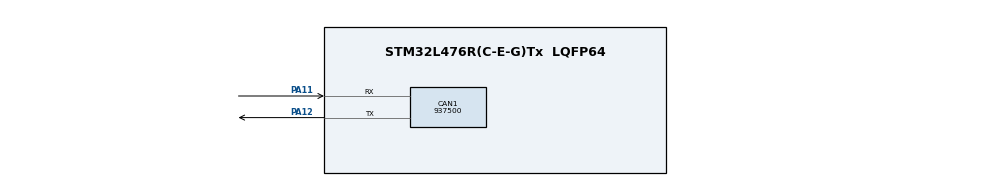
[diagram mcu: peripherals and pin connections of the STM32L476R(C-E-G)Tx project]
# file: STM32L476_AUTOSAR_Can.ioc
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CAN1.CalculateBaudRate=937500
CAN1.CalculateTimeBit=1066
CAN1.CalculateTimeQuantum=355.55555555555554
Mcu.Family=STM32L4
Mcu.Name=STM32L476R(C-E-G)Tx
Mcu.Package=LQFP64
NVIC.PriorityGroup=NVIC_PRIORITYGROUP_4
PA11.Mode=CAN_Activate
PA11.Signal=CAN1_RX
PA12.Mode=CAN_Activate
PA12.Signal=CAN1_TX
PC14-OSC32_IN\ (PC14).Mode=LSE-External-Oscillator
PC14-OSC32_IN\ (PC14).Signal=RCC_OSC32_IN
PC15-OSC32_OUT\ (PC15).Mode=LSE-External-Oscillator
PC15-OSC32_OUT\ (PC15).Signal=RCC_OSC32_OUT
PH0-OSC_IN\ (PH0).Mode=HSE-External-Oscillator
PH0-OSC_IN\ (PH0).Signal=RCC_OSC_IN
PH1-OSC_OUT\ (PH1).Mode=HSE-External-Oscillator
PH1-OSC_OUT\ (PH1).Signal=RCC_OSC_OUT
ProjectManager.HeapSize=0x200
ProjectManager.StackSize=0x400
ProjectManager.TargetToolchain=MDK-ARM V5.32
RCC.ADCFreq_Value=16000000
RCC.AHBFreq_Value=45000000
RCC.APB1Freq_Value=45000000
RCC.APB1TimFreq_Value=45000000
RCC.APB2Freq_Value=45000000
RCC.APB2TimFreq_Value=45000000
RCC.CortexFreq_Value=45000000
RCC.HCLKFreq_Value=45000000
RCC.HSE_VALUE=8000000
RCC.HSI_VALUE=16000000
RCC.MSI_VALUE=4000000
RCC.PLLM=4
RCC.PLLN=45
RCC.PLLR=RCC_PLLR_DIV4
RCC.PLLSourceVirtual=RCC_PLLSOURCE_HSI
RCC.PREFETCH_ENABLE=1
RCC.SYSCLKFreq_VALUE=45000000
RCC.SYSCLKSource=RCC_SYSCLKSOURCE_PLLCLK
RCC.USBFreq_Value=16000000
RCC.VCOOutputFreq_Value=180000000
board=NUCLEO-L476RG

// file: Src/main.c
/* USER CODE BEGIN Header */
/**
  ******************************************************************************
  * @file           : main.c
  * @brief          : Main program body
  ******************************************************************************
  * @attention
  *
  * Copyright (c) 2025 STMicroelectronics.
  * All rights reserved.
  *
  * This software is licensed under terms that can be found in the LICENSE file
  * in the root directory of this software component.
  * If no LICENSE file comes with this software, it is provided AS-IS.
  *
  ******************************************************************************
  */
/* USER CODE END Header */
#include "main.h"

/* USER CODE BEGIN Includes */
#include "Can.h"
/* USER CODE END Includes */

CAN_HandleTypeDef hcan1;

void SystemClock_Config(void);
static void MX_GPIO_Init(void);
static void MX_CAN1_Init(void);

int main(void)
{

  /* MCU Configuration--------------------------------------------------------*/

  /* Reset of all peripherals, Initializes the Flash interface and the Systick. */
  HAL_Init();

  /* Configure the system clock */
  SystemClock_Config();

  /* Initialize all configured peripherals */
  MX_GPIO_Init();
  MX_CAN1_Init();

  /* Infinite loop */
  while (1)
  {

  }
}

void SystemClock_Config(void)
{
  LL_FLASH_SetLatency(LL_FLASH_LATENCY_2);
  while(LL_FLASH_GetLatency()!= LL_FLASH_LATENCY_2)
  {
  }
  LL_PWR_SetRegulVoltageScaling(LL_PWR_REGU_VOLTAGE_SCALE1);
  while (LL_PWR_IsActiveFlag_VOS() != 0)
  {
  }
  LL_RCC_HSI_Enable();

   /* Wait till HSI is ready */
  while(LL_RCC_HSI_IsReady() != 1)
  {

  }
  LL_RCC_HSI_SetCalibTrimming(16);
  LL_RCC_PLL_ConfigDomain_SYS(LL_RCC_PLLSOURCE_HSI, LL_RCC_PLLM_DIV_4, 45, LL_RCC_PLLR_DIV_4);
  LL_RCC_PLL_EnableDomain_SYS();
  LL_RCC_PLL_Enable();

   /* Wait till PLL is ready */
  while(LL_RCC_PLL_IsReady() != 1)
  {

  }
  LL_RCC_SetSysClkSource(LL_RCC_SYS_CLKSOURCE_PLL);

   /* Wait till System clock is ready */
  while(LL_RCC_GetSysClkSource() != LL_RCC_SYS_CLKSOURCE_STATUS_PLL)
  {

  }
  LL_RCC_SetAHBPrescaler(LL_RCC_SYSCLK_DIV_1);
  LL_RCC_SetAPB1Prescaler(LL_RCC_APB1_DIV_1);
  LL_RCC_SetAPB2Prescaler(LL_RCC_APB2_DIV_1);
  LL_SetSystemCoreClock(45000000);

   /* Update the time base */
  if (HAL_InitTick (TICK_INT_PRIORITY) != HAL_OK)
  {
    Error_Handler();
  }
}

static void MX_CAN1_Init(void)
{

  hcan1.Instance = CAN1;
  hcan1.Init.Prescaler = 16;
  hcan1.Init.Mode = CAN_MODE_NORMAL;
  hcan1.Init.SyncJumpWidth = CAN_SJW_1TQ;
  hcan1.Init.TimeSeg1 = CAN_BS1_1TQ;
  hcan1.Init.TimeSeg2 = CAN_BS2_1TQ;
  hcan1.Init.TimeTriggeredMode = DISABLE;
  hcan1.Init.AutoBusOff = DISABLE;
  hcan1.Init.AutoWakeUp = DISABLE;
  hcan1.Init.AutoRetransmission = DISABLE;
  hcan1.Init.ReceiveFifoLocked = DISABLE;
  hcan1.Init.TransmitFifoPriority = DISABLE;
  if (HAL_CAN_Init(&hcan1) != HAL_OK)
  {
    Error_Handler();
  }

}

static void MX_GPIO_Init(void)
{

  /* GPIO Ports Clock Enable */
  LL_AHB2_GRP1_EnableClock(LL_AHB2_GRP1_PERIPH_GPIOC);
  LL_AHB2_GRP1_EnableClock(LL_AHB2_GRP1_PERIPH_GPIOH);
  LL_AHB2_GRP1_EnableClock(LL_AHB2_GRP1_PERIPH_GPIOA);

}

void Error_Handler(void)
{
  __disable_irq();
  while (1)
  {
  }
}
